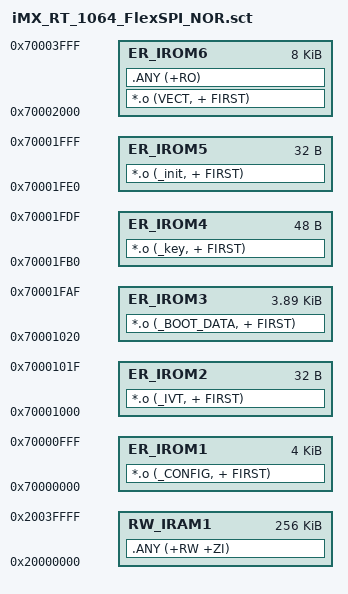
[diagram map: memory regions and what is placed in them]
;/* iMX_RT_1064_FlexSPI_NOR.sct - for iMX RT 1064 running from FlexSPI NOR    */
;/* 512k RAM                                                                  */

LR_IROM1 0x70000000 0x00001000  {    ; load region size_region
  ER_IROM1 0x70000000 0x00001000  {  ; load address = execution address
   *.o (_CONFIG, + FIRST)
  }
  RW_IRAM1 0x20000000 0x00040000  {  ; RW data
   .ANY (+RW +ZI)
  }
}

LR_IROM2 0x70001000 0x00000020  {    ; load region size_region
  ER_IROM2 0x70001000 0x00000020  {  ; load address = execution address
   *.o (_IVT, + FIRST)
  }
}

LR_IROM3 0x70001020 0x00000f90  {    ; load region size_region
  ER_IROM3 0x70001020 0x00000f90  {  ; load address = execution address
   *.o (_BOOT_DATA, + FIRST)
  }
}

LR_IROM4 0x70001fb0 0x00000030  {    ; load region size_region
  ER_IROM4 0x70001fb0 0x00000030  {  ; load address = execution address
   *.o (_key, + FIRST)
  }
}

LR_IROM5 0x70001fe0 0x00000020  {    ; load region size_region
  ER_IROM5 0x70001fe0 0x00000020  {  ; load address = execution address
   *.o (_init, + FIRST)
  }
}

LR_IROM6 0x70002000 0x00002000  {    ; load region size_region
  ER_IROM6 0x70002000 0x00002000  {  ; load address = execution address
   *.o (VECT, + FIRST)
   .ANY (+RO)
  }
}


